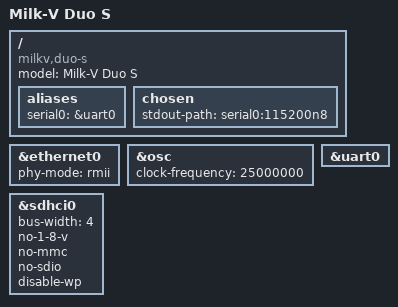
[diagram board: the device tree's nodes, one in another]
// SPDX-License-Identifier: (GPL-2.0 OR MIT)
/*
 * Copyright (C) 2026 Andrei Lalaev <andrey.lalaev@gmail.com>
 */

/dts-v1/;

#include "sg2000.dtsi"

/ {
	model = "Milk-V Duo S";
	compatible = "milkv,duo-s", "sophgo,sg2000";

	aliases {
		serial0 = &uart0;
	};

	chosen {
		stdout-path = "serial0:115200n8";
	};
};

&ethernet0 {
	status = "okay";
	phy-mode = "rmii";
};

&osc {
	clock-frequency = <25000000>;
};

&sdhci0 {
	status = "okay";
	bus-width = <4>;
	no-1-8-v;
	no-mmc;
	no-sdio;
	disable-wp;
};

&uart0 {
	status = "okay";
};
